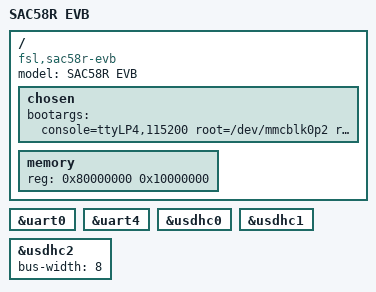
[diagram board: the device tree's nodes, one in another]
/*
 * Copyright 2014 Freescale Semiconductor, Inc.
 *
 * This program is free software; you can redistribute it and/or modify
 * it under the terms of the GNU General Public License as published by
 * the Free Software Foundation; either version 2 of the License, or
 * (at your option) any later version.
 */

/dts-v1/;
#include "sac58r.dtsi"

/ {
	model = "SAC58R EVB";
	compatible = "fsl,sac58r-evb", "fsl,sac58r";

	chosen {
		bootargs = "console=ttyLP4,115200 root=/dev/mmcblk0p2 rootwait rw";
	};

	memory {
		reg = <0x80000000 0x10000000>;
	};
};

&uart0 {
	status = "okay";
};

&uart4 {
	status = "okay";
};

&usdhc0 {
	status = "okay";
};

&usdhc1 {
	status = "okay";
};

&usdhc2 {
	status = "okay";
	bus-width = <8>;
};
